# STM32C031 register map
File version: 0.2
CPU: CM0 r0p0, little endian, MPU, FPU, 4 interrupt priority bits
Registers are 32-bit, read-write, reset 0x0 unless marked. A register's access mark holds for its fields unless they carry their own. Offsets are from the block's base; [hi:lo] are bit positions; {n}, {i} and the like mark numbered series.

## DBG — DBG register block
Base 0x40015800
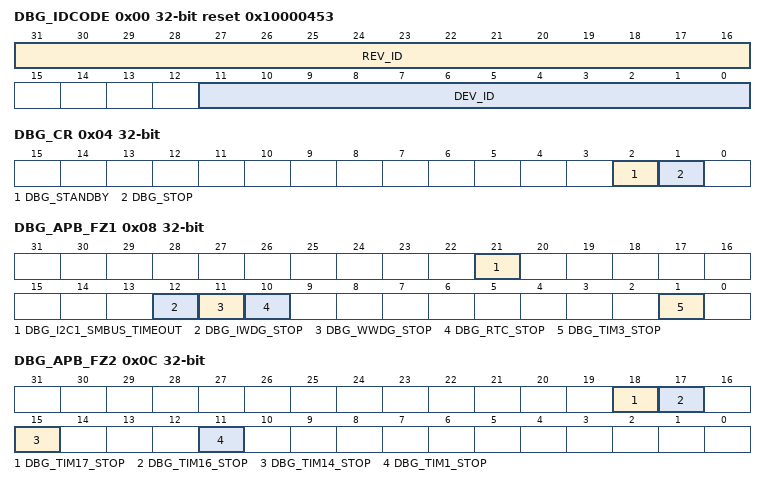
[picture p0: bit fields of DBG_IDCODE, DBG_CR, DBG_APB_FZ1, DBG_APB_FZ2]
0x00 DBG_IDCODE ro reset 0x10000453 — DBG device ID code register
  [31:16] REV_ID — Revision identifier This bitfield indicates the revision of the device.
  [11:0] DEV_ID — Device identifier This bitfield indicates the device ID.
0x04 DBG_CR — DBG configuration register
  [2] DBG_STANDBY — Debug Standby and Shutdown modes
  [1] DBG_STOP — Debug Stop mode
0x08 DBG_APB_FZ1 — DBG APB freeze register 1
  [21] DBG_I2C1_SMBUS_TIMEOUT — SMBUS timeout when core is halted
    0=Same behavior as in normal mode; 1=The SMBUS timeout is frozen
  [12] DBG_IWDG_STOP — Clocking of IWDG counter when the core is halted This bit enables/disables the clock to the counter of IWDG when the core is halted:
    0=Enable; 1=Disable
  [11] DBG_WWDG_STOP — Clocking of WWDG counter when the core is halted This bit enables/disables the clock to the counter of WWDG when the core is halted:
    0=Enable; 1=Disable
  [10] DBG_RTC_STOP — Clocking of RTC counter when the core is halted This bit enables/disables the clock to the counter of RTC when the core is halted:
    0=Enable; 1=Disable
  [1] DBG_TIM3_STOP — Clocking of TIM3 counter when the core is halted This bit enables/disables the clock to the counter of TIM3 when the core is halted:
    0=Enable; 1=Disable
0x0C DBG_APB_FZ2 — DBG APB freeze register 2
  [all] fields
    0=Enable; 1=Disable
  [18] DBG_TIM17_STOP — Clocking of TIM17 counter when the core is halted This bit enables/disables the clock to the counter of TIM17 when the core is halted:
  [17] DBG_TIM16_STOP — Clocking of TIM16 counter when the core is halted This bit enables/disables the clock to the counter of TIM16 when the core is halted:
  [15] DBG_TIM14_STOP — Clocking of TIM14 counter when the core is halted This bit enables/disables the clock to the counter of TIM14 when the core is halted:
  [11] DBG_TIM1_STOP — Clocking of TIM1 counter when the core is halted This bit enables/disables the clock to the counter of TIM1 when the core is halted:

## EXTI — EXTI address block description
Base 0x40021800
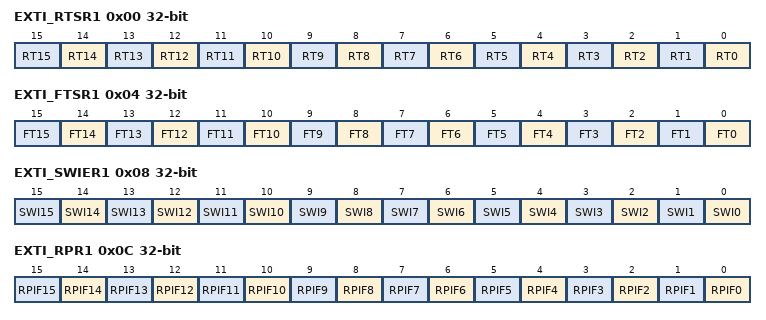
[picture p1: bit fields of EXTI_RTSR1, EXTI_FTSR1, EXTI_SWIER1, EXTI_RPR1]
0x00 EXTI_RTSR1 — EXTI rising trigger selection register
  [all] fields
    0=Disable; 1=Enable
  [n] RT{n} (n=0..15) — Rising trigger event configuration bit of configurable line x (x = 15 to 0) Each bit enables/disables the rising edge trigger for the event and interrupt on the corresponding line.
0x04 EXTI_FTSR1 — EXTI falling trigger selection register 1
  [all] fields
    0=Disable; 1=Enable
  [n] FT{n} (n=0..15) — Falling trigger event configuration bit of configurable line x (x = 15 to 0). Each bit enables/disables the falling edge trigger for the event and interrupt on the corresponding line.
0x08 EXTI_SWIER1 — EXTI software interrupt event register 1
  [all] fields
    0=No effect; 1=Rising edge event generated on the corresponding line, followed by an interrupt
  [n] SWI{n} (n=0..15) — Software rising edge event trigger on line x (x = 15 to 0) Setting of any bit by software triggers a rising edge event on the corresponding line x, resulting in an interrupt, independently of EXTI_RTSR1 and EXTI_FTSR1 settings. The bits are automatically cleared by HW. Reading of any bit always returns 0.
0x0C EXTI_RPR1 — EXTI rising edge pending register 1
  [all] fields
    0=No rising edge trigger request occurred; 1=Rising edge trigger request occurred
  [n] RPIF{n} (n=0..15) — Rising edge event pending for configurable line x (x = 15 to 0) Each bit is set upon a rising edge event generated by hardware or by software (through the EXTI_SWIER1 register) on the corresponding line. Each bit is cleared by writing 1 into it.
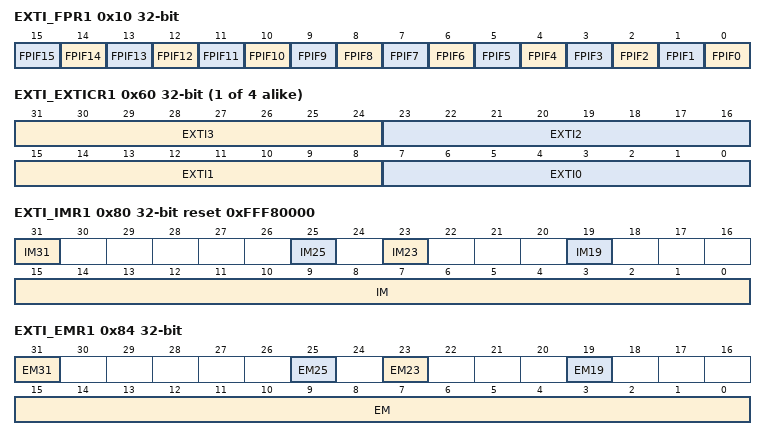
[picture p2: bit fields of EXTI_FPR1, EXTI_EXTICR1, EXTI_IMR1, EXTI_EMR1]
0x10 EXTI_FPR1 — EXTI falling edge pending register 1
  [all] fields
    0=No falling edge trigger request occurred; 1=Falling edge trigger request occurred
  [n] FPIF{n} (n=0..15) — Falling edge event pending for configurable line x (x = 15 to 0) Each bit is set upon a falling edge event generated by hardware or by software (through the EXTI_SWIER1 register) on the corresponding line. Each bit is cleared by writing 1 into it.
{0x5C+4i} EXTI_EXTICR{i} (i=1..4) — EXTI external interrupt selection register
  [31:24] EXTI3
  [23:16] EXTI2
  [15:8] EXTI1
  [7:0] EXTI0 — EXTIm GPIO port selection (m = 4 * (x - 1)) These bits are written by software to select the source input for EXTIm external interrupt. Other: reserved
    0=PA[m] pin; 1=PB[m] pin; 2=PC[m] pin; 3=PD[m] pin; 5=PF[m] pin
0x80 EXTI_IMR1 reset 0xFFF80000 — EXTI CPU wakeup with interrupt mask register
  [31] IM31
  [25] IM25
  [23] IM23
  [19] IM19
  [15:0] IM — CPU wakeup with interrupt mask
0x84 EXTI_EMR1 — EXTI CPU wakeup with event mask register
  [31] EM31
  [25] EM25
  [23] EM23
  [19] EM19
  [15:0] EM — CPU wakeup with event generation mask

## WWDG — WWDG register block
Base 0x40002C00
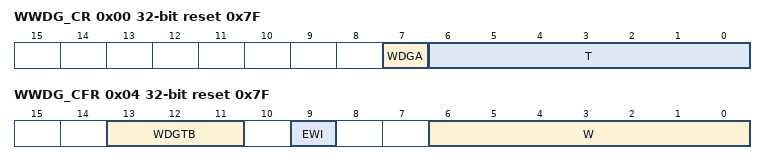
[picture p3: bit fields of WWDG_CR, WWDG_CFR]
0x00 WWDG_CR reset 0x7F — WWDG control register
  [7] WDGA — Activation bit This bit is set by software and only cleared by hardware after a reset. When WDGA = 1, the watchdog can generate a reset.
    0=Watchdog disabled; 1=Watchdog enabled
  [6:0] T — 7-bit counter (MSB to LSB) These bits contain the value of the watchdog counter, decremented every (4096 x 2WDGTB[1:0]) PCLK cycles. A reset is produced when it is decremented from 0x40 to 0x3F (T6 becomes cleared).
0x04 WWDG_CFR reset 0x7F — WWDG configuration register
  [13:11] WDGTB — Timer base The timebase of the prescaler can be modified as follows:
    0=CK counter clock (PCLK div 4096) div 1; 1=CK counter clock (PCLK div 4096) div 2; 2=CK counter clock (PCLK div 4096) div 4; 3=CK counter clock (PCLK div 4096) div 8; 4=CK counter clock (PCLK div 4096) div 16; 5=CK counter clock (PCLK div 4096) div 32; 6=CK counter clock (PCLK div 4096) div 64; 7=CK counter clock (PCLK div 4096) div 128
  [9] EWI — Early wakeup interrupt When set, an interrupt occurs whenever the counter reaches the value 0x40. This interrupt is only cleared by hardware after a reset.
  [6:0] W — 7-bit window value These bits contain the window value to be compared with the down-counter.
0x08 WWDG_SR — WWDG status register
  [0] EWIF — Early wakeup interrupt flag This bit is set by hardware when the counter has reached the value 0x40. It must be cleared by software by writing ‘0’. Writing ‘1’ has no effect. This bit is also set if the interrupt is not enabled.
